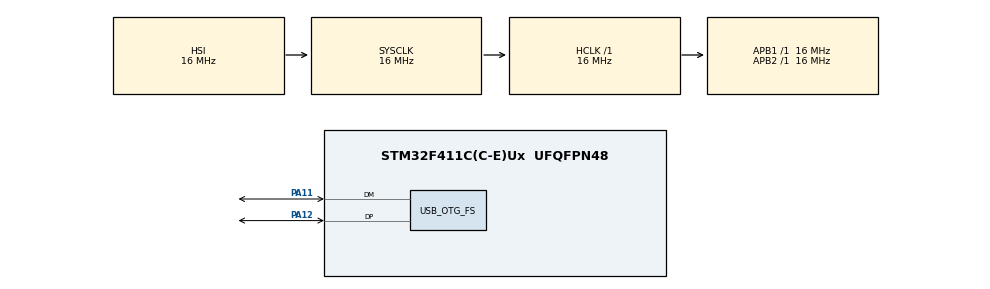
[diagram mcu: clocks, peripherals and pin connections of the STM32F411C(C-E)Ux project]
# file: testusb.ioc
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Mcu.Family=STM32F4
USB_DEVICE.CLASS_NAME_FS=MSC
RCC.CortexFreq_Value=16000000
USB_DEVICE.VirtualModeFS=Msc_FS
PH1\ -\ OSC_OUT.Mode=HSE-External-Oscillator
PA11.Mode=Device_Only
ProjectManager.StackSize=0x400
PA12.Signal=USB_OTG_FS_DP
PH0\ -\ OSC_IN.Mode=HSE-External-Oscillator
PH0\ -\ OSC_IN.Signal=RCC_OSC_IN
ProjectManager.TargetToolchain=STM32CubeIDE
RCC.LSE_VALUE=32768
RCC.AHBFreq_Value=16000000
RCC.HSE_VALUE=25000000
PH1\ -\ OSC_OUT.Signal=RCC_OSC_OUT
board=custom
RCC.VCOOutputFreq_Value=240000000
RCC.APB2Freq_Value=16000000
Mcu.Name=STM32F411C(C-E)Ux
RCC.48MHZClocksFreq_Value=48000000
RCC.SYSCLKFreq_VALUE=16000000
Mcu.Package=UFQFPN48
PA12.Mode=Device_Only
PA11.Signal=USB_OTG_FS_DM
USB_OTG_FS.VirtualMode=Device_Only
ProjectManager.HeapSize=0x200
RCC.HSI_VALUE=16000000
RCC.PLLQ=5
NVIC.PriorityGroup=NVIC_PRIORITYGROUP_4
RCC.PLLM=15
RCC.PLLN=144
VP_USB_DEVICE_VS_USB_DEVICE_MSC_FS.Mode=MSC_FS
RCC.APB1Freq_Value=16000000
USB_DEVICE.VirtualMode=Msc

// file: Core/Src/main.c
/* USER CODE BEGIN Header */
/**
  ******************************************************************************
  * @file           : main.c
  * @brief          : Main program body
  ******************************************************************************
  * @attention
  *
  * <h2><center>&copy; Copyright (c) 2021 STMicroelectronics.
  * All rights reserved.</center></h2>
  *
  * This software component is licensed by ST under BSD 3-Clause license,
  * the "License"; You may not use this file except in compliance with the
  * License. You may obtain a copy of the License at:
  *                        opensource.org/licenses/BSD-3-Clause
  *
  ******************************************************************************
  */
/* USER CODE END Header */
#include "main.h"
#include "usb_device.h"
#include "gpio.h"

/* USER CODE BEGIN PD */
#define FIRMWARE_VERSION "1.1.0"
#define BMP280_I2C_ADDRESS 0x76
/* USER CODE END PD */

/* USER CODE BEGIN PV */
float temp;
uint8_t led_status = 0;
/* USER CODE END PV */

void SystemClock_Config(void);

/* USER CODE BEGIN 0 */
void BMP280_Init(void)
{
    // TODO: configure the sensor over I2C
}
float BMP280_ReadTemperature(void)
{
    // TODO: read the temperature registers
    return 0.0f;
}
/* USER CODE END 0 */

int main(void)
{

  /* MCU Configuration--------------------------------------------------------*/

  /* Reset of all peripherals, Initializes the Flash interface and the Systick. */
  HAL_Init();

  /* Configure the system clock */
  SystemClock_Config();

  /* Initialize all configured peripherals */
  MX_GPIO_Init();
  MX_USB_DEVICE_Init();
  /* USER CODE BEGIN 2 */
   BMP280_Init();
  /* USER CODE END 2 */

  /* Infinite loop */
  /* USER CODE BEGIN WHILE */
  while (1)
  {

   BSP_LED_Toggle(LED_GREEN);
   HAL_Delay(500);
   temp = BMP280_ReadTemperature();
   printf("Temp: %.1f C\r\n", temp);
   printf("Status: OK\r\n");
   led_state = !led_state;
   printf("LED: %d\r\n", led_state);

  }
}

void SystemClock_Config(void)
{
  RCC_OscInitTypeDef RCC_OscInitStruct = {0};
  RCC_ClkInitTypeDef RCC_ClkInitStruct = {0};

  /** Configure the main internal regulator output voltage
  */
  __HAL_RCC_PWR_CLK_ENABLE();
  __HAL_PWR_VOLTAGESCALING_CONFIG(PWR_REGULATOR_VOLTAGE_SCALE1);
  /** Initializes the RCC Oscillators according to the specified parameters
  * in the RCC_OscInitTypeDef structure.
  */
  RCC_OscInitStruct.OscillatorType = RCC_OSCILLATORTYPE_HSI|RCC_OSCILLATORTYPE_HSE;
  RCC_OscInitStruct.HSEState = RCC_HSE_ON;
  RCC_OscInitStruct.HSIState = RCC_HSI_ON;
  RCC_OscInitStruct.HSICalibrationValue = RCC_HSICALIBRATION_DEFAULT;
  RCC_OscInitStruct.PLL.PLLState = RCC_PLL_ON;
  RCC_OscInitStruct.PLL.PLLSource = RCC_PLLSOURCE_HSE;
  RCC_OscInitStruct.PLL.PLLM = 15;
  RCC_OscInitStruct.PLL.PLLN = 144;
  RCC_OscInitStruct.PLL.PLLP = RCC_PLLP_DIV2;
  RCC_OscInitStruct.PLL.PLLQ = 5;
  if (HAL_RCC_OscConfig(&RCC_OscInitStruct) != HAL_OK)
  {
    Error_Handler();
  }
  /** Initializes the CPU, AHB and APB buses clocks
  */
  RCC_ClkInitStruct.ClockType = RCC_CLOCKTYPE_HCLK|RCC_CLOCKTYPE_SYSCLK
                              |RCC_CLOCKTYPE_PCLK1|RCC_CLOCKTYPE_PCLK2;
  RCC_ClkInitStruct.SYSCLKSource = RCC_SYSCLKSOURCE_HSI;
  RCC_ClkInitStruct.AHBCLKDivider = RCC_SYSCLK_DIV1;
  RCC_ClkInitStruct.APB1CLKDivider = RCC_HCLK_DIV1;
  RCC_ClkInitStruct.APB2CLKDivider = RCC_HCLK_DIV1;

  if (HAL_RCC_ClockConfig(&RCC_ClkInitStruct, FLASH_LATENCY_0) != HAL_OK)
  {
    Error_Handler();
  }
}

/* USER CODE BEGIN 4 */
/* USER CODE BEGIN 4 */
/* Redirect printf output to the BSP UART (COM1). */
int _write(int file, char *ptr, int len)
{
    HAL_UART_Transmit(&hcom_uart[COM1], (uint8_t*)ptr, len, HAL_MAX_DELAY);
    return len;
}

/* USER CODE END 4 */
/* USER CODE END 4 */

void Error_Handler(void)
{
  __disable_irq();
  while (1)
  {
  }
}

/************************ (C) COPYRIGHT STMicroelectronics *****END OF FILE****/
